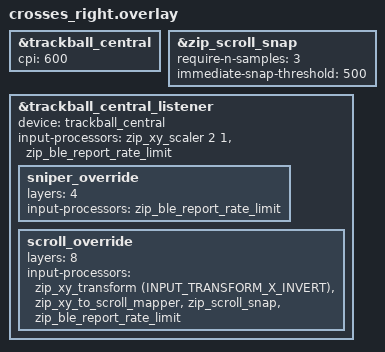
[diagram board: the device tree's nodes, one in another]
#include <scroll-snap.dtsi>

&trackball_central {
    cpi = <600>;
};

&zip_scroll_snap {
    // The default is 10. Lowering this makes it decide much faster.
    require-n-samples = <3>; 
    
    // The default is 1500. This is the velocity/distance threshold that bypasses 
    // the sample requirement and forces an instant snap. Lowering this makes 
    // quick flicks snap instantly.
    immediate-snap-threshold = <500>; 
};

&trackball_central_listener {
    status = "okay";
    device = <&trackball_central>;
    input-processors 
        = <&zip_xy_scaler 2 1>
        , <&zip_ble_report_rate_limit>;
		
	sniper_override {
        layers = <4>;
        input-processors = <&zip_ble_report_rate_limit>;
    };
	
	scroll_override {
		layers = <8>;
	    input-processors
			= <&zip_xy_transform (INPUT_TRANSFORM_X_INVERT)>
			, <&zip_xy_to_scroll_mapper>
			, <&zip_scroll_snap>
			, <&zip_ble_report_rate_limit>;
	};
};
